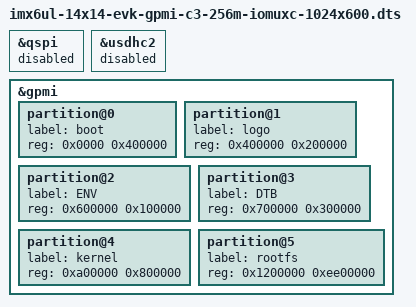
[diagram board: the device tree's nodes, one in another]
/*
 * Copyright (C) 2015 Freescale Semiconductor, Inc.
 *
 * This program is free software; you can redistribute it and/or modify
 * it under the terms of the GNU General Public License version 2 as
 * published by the Free Software Foundation.
 */

#include "imx6ul-14x14-evk-emmc-c3-iomuxc-1024x600.dts"
&qspi{
			status = "disabled";
};

&usdhc2 {
			status = "disabled";
};

&gpmi {
			status = "okay";
			partition@0{
	          		label = "boot";
				reg = <0x0000 0x400000>; /*4M*/
			};
			partition@1{
				label = "logo";
				reg = <0x400000 0x200000>; /*2M*/
		    	};
			partition@2{
				label = "ENV";
				reg = <0x600000 0x100000>; /*1M*/
			};
			partition@3{
				label = "DTB";
				reg = <0x700000 0x300000>; /*3M*/
			};
			partition@4{
				label = "kernel";
				reg = <0xa00000 0x800000>; /*8M*/
			};
			partition@5{
				label = "rootfs";
				reg = <0x1200000 0xee00000>;
			};
};


